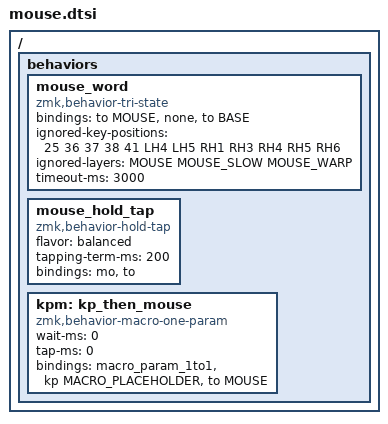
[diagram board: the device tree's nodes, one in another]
/ {
	behaviors {

		mouse_word: mouse_word {
			compatible = "zmk,behavior-tri-state";
			#binding-cells = <0>;
			bindings = <&to MOUSE>, <&none>, <&to BASE>;
			ignored-key-positions = <
				/* left */
				        25
			       36 37 38
				/* right */
					       41 
				/* thumbs */
			LH4 LH5
			RH1 RH3 RH4 RH5 RH6
			>;
			ignored-layers = <MOUSE MOUSE_SLOW MOUSE_WARP>;
			timeout-ms = <3000>;
		};

		mouse_hold_tap: mouse_hold_tap {
		  compatible = "zmk,behavior-hold-tap";
		  #binding-cells = <2>;
		  flavor = "balanced";
		  tapping-term-ms = <200>;
		  bindings = <&mo>, <&to>;
		};

		#define mouse mouse_hold_tap MOUSE MOUSE


		kpm: kp_then_mouse {
			compatible = "zmk,behavior-macro-one-param";
			#binding-cells = <1>;
			wait-ms = <0>;
			tap-ms = <0>;
			bindings = <&macro_param_1to1>, <&kp MACRO_PLACEHOLDER>, <&to MOUSE>;
		};
	};
};
